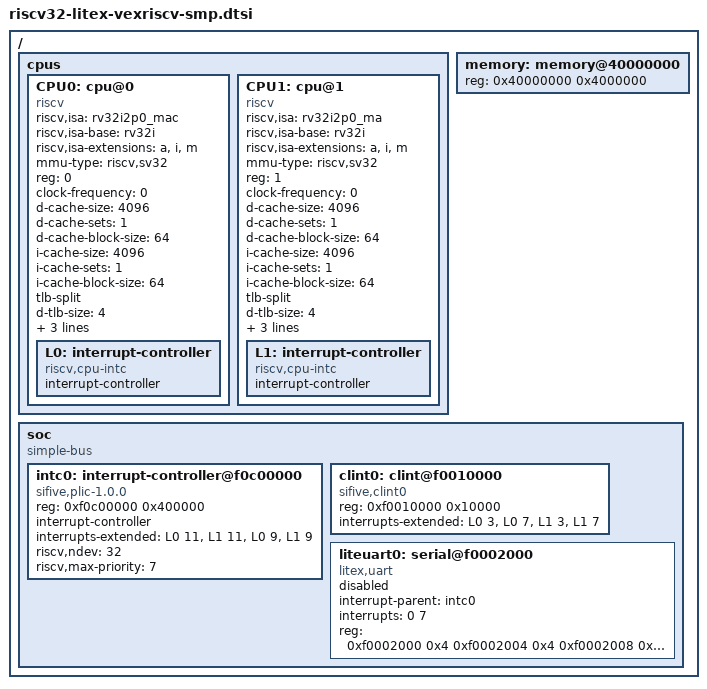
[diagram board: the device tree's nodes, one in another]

/dts-v1/;

/ {
	#address-cells = <1>;
	#size-cells    = <1>;

	cpus {
		#address-cells = <1>;
		#size-cells    = <0>;

		CPU0: cpu@0 {
			device_type = "cpu";
			compatible = "riscv";
			riscv,isa = "rv32i2p0_mac";
			riscv,isa-base = "rv32i";
			riscv,isa-extensions = "a", "i", "m";
			mmu-type = "riscv,sv32";
			reg = <0>;
			clock-frequency = <0>;
			status = "okay";
			
			d-cache-size = <4096>;
			d-cache-sets = <1>;
			d-cache-block-size = <64>;

			i-cache-size = <4096>;
			i-cache-sets = <1>;
			i-cache-block-size = <64>;

			
			tlb-split;
			d-tlb-size = <4>;
			d-tlb-sets = <4>;

			i-tlb-size = <4>;
			i-tlb-sets = <4>;

			
			L0: interrupt-controller {
				#address-cells = <0>;
				#interrupt-cells = <1>;
				interrupt-controller;
				compatible = "riscv,cpu-intc";
			};
		};

		CPU1: cpu@1 {
			device_type = "cpu";
			compatible = "riscv";
			riscv,isa = "rv32imas";
			riscv,isa = "rv32i2p0_ma";
			riscv,isa-base = "rv32i";
			riscv,isa-extensions = "a", "i", "m";
			mmu-type = "riscv,sv32";
			reg = <1>;
			clock-frequency = <0>;
			status = "okay";
			
			d-cache-size = <4096>;
			d-cache-sets = <1>;
			d-cache-block-size = <64>;

			i-cache-size = <4096>;
			i-cache-sets = <1>;
			i-cache-block-size = <64>;

			
			tlb-split;
			d-tlb-size = <4>;
			d-tlb-sets = <4>;

			i-tlb-size = <4>;
			i-tlb-sets = <4>;

			
			L1: interrupt-controller {
				#address-cells = <0>;
				#interrupt-cells = <1>;
				interrupt-controller;
				compatible = "riscv,cpu-intc";
			};
		};
	};

	memory: memory@40000000 {
		device_type = "memory";
		reg = <0x40000000 0x4000000>;
	};

	soc {
		#address-cells = <1>;
		#size-cells    = <1>;
		compatible = "simple-bus";
	//	interrupt-parent = <&intc0>;
		ranges;

	//	soc_ctrl0: soc_controller@f0000000 {
	//		compatible = "litex,soc-controller";
	//		reg = <0xf0000000 0xc>;
	//		status = "okay";
	//	};

		intc0: interrupt-controller@f0c00000 {
			compatible = "sifive,plic-1.0.0";
			reg = <0xf0c00000 0x400000>;
			#address-cells = <1>;
			#interrupt-cells = <2>;
			interrupt-controller;
			interrupts-extended = <&L0 11 &L1 11 &L0 9 &L1 9>;
			riscv,ndev = <32>;
			riscv,max-priority = <7>;
		};
		
		clint0: clint@f0010000 {
            compatible = "sifive,clint0";
            reg = <0xf0010000 0x10000>;
            interrupts-extended = <&L0 3 &L0 7 &L1 3 &L1 7>;
			interrupt-names = "soft0", "timer0", "soft1", "timer1";
        };

		liteuart0: serial@f0002000 {
			compatible = "litex,uart";
			interrupt-parent = <&intc0>;
			interrupts = <0 7>;
			reg = <
				0xf0002000 0x4
				0xf0002004 0x4
				0xf0002008 0x4
				0xf000200c 0x4
				0xf0002010 0x4
				0xf0002014 0x4
				0xf0002018 0x4
				0xf000201c 0x4>;
			reg-names =
				"rxtx",
				"txfull",
				"rxempty",
				"ev_status",
				"ev_pending",
				"ev_enable",
				"txempty",
				"rxfull";
			status = "disabled"; 
		};
	};
};
